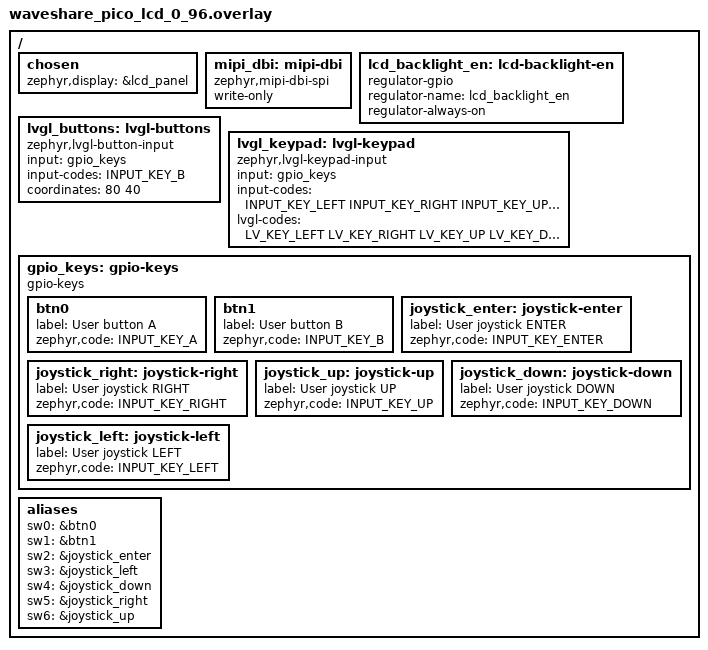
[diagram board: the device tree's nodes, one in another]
/*
 * SPDX-FileCopyrightText: Copyright (c) 2023-2026 TiaC Systems
 * SPDX-License-Identifier: Apache-2.0
 */

#include <zephyr/dt-bindings/input/input-event-codes.h>
#include <zephyr/dt-bindings/lvgl/lvgl.h>

/ {
	chosen {
		zephyr,display = &lcd_panel;
	};

	mipi_dbi: mipi-dbi {
		compatible = "zephyr,mipi-dbi-spi";
		write-only;
	};

	lcd_backlight_en: lcd-backlight-en {
		compatible = "regulator-gpio";
		regulator-name = "lcd_backlight_en";
		regulator-always-on;
	};

	lvgl_buttons: lvgl-buttons {
		compatible = "zephyr,lvgl-button-input";
		input = <&gpio_keys>;
		input-codes = <INPUT_KEY_B>;
		coordinates = <80 40>;
	};

	lvgl_keypad: lvgl-keypad {
		compatible = "zephyr,lvgl-keypad-input";
		input = <&gpio_keys>;
		input-codes = <INPUT_KEY_LEFT INPUT_KEY_RIGHT
			       INPUT_KEY_UP INPUT_KEY_DOWN
			       INPUT_KEY_ENTER>;
		lvgl-codes = <LV_KEY_LEFT LV_KEY_RIGHT
			      LV_KEY_UP LV_KEY_DOWN
			      LV_KEY_ENTER>;
	};

	/delete-node/ gpio_keys;
	/delete-node/ gpio-keys;
	gpio_keys: gpio-keys {
		compatible = "gpio-keys";
		btn0: btn0 {
			label = "User button A";
			zephyr,code = <INPUT_KEY_A>;
		};
		btn1: btn1 {
			label = "User button B";
			zephyr,code = <INPUT_KEY_B>;
		};
		joystick_enter: joystick-enter {
			label = "User joystick ENTER";
			zephyr,code = <INPUT_KEY_ENTER>;
		};
		joystick_right: joystick-right {
			label = "User joystick RIGHT";
			zephyr,code = <INPUT_KEY_RIGHT>;
		};
		joystick_up: joystick-up {
			label = "User joystick UP";
			zephyr,code = <INPUT_KEY_UP>;
		};
		joystick_down: joystick-down {
			label = "User joystick DOWN";
			zephyr,code = <INPUT_KEY_DOWN>;
		};
		joystick_left: joystick-left {
			label = "User joystick LEFT";
			zephyr,code = <INPUT_KEY_LEFT>;
		};
	};

	aliases {
		/delete-property/ sw0;
		sw0 = &btn0;
		sw1 = &btn1;
		sw2 = &joystick_enter;
		sw3 = &joystick_left;
		sw4 = &joystick_down;
		sw5 = &joystick_right;
		sw6 = &joystick_up;
	};
};
